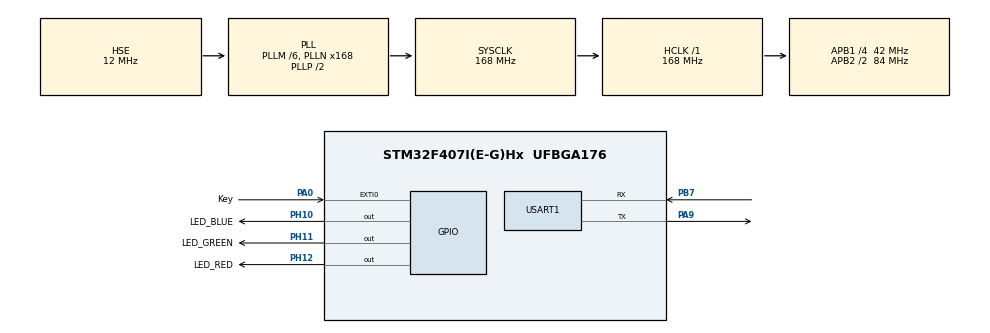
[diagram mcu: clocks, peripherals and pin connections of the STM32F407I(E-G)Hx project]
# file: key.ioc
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FREERTOS.BinarySemaphores01=KeyBinarySem,Dynamic,NULL,Depleted
FREERTOS.CountingSemaphores01=cryptoChip,3,Dynamic,NULL,3
FREERTOS.Queues01=usartQueue,32,AppMsg_t*,0,Dynamic,NULL,NULL
FREERTOS.Tasks01=defaultTask,24,128,StartDefaultTask,Default,NULL,Dynamic,NULL,NULL;LED_Flash_Task,8,128,Start_LED_Flash_Task,As weak,NULL,Dynamic,NULL,NULL;KeyTask,41,128,StartKeyTask,As weak,hkey,Dynamic,NULL,NULL;msgHandleTask,8,128,StartMsgHandleTask,As weak,NULL,Dynamic,NULL,NULL;myTask01,8,128,StartTask01,As weak,NULL,Dynamic,NULL,NULL;myTask02,8,128,StartTask02,As weak,NULL,Dynamic,NULL,NULL;myTask03,8,128,StartTask03,As weak,NULL,Dynamic,NULL,NULL
Mcu.Family=STM32F4
Mcu.Name=STM32F407I(E-G)Hx
Mcu.Package=UFBGA176
NVIC.EXTI0_IRQn=true\:5\:0\:false\:false\:true\:true\:true\:true\:true
NVIC.PriorityGroup=NVIC_PRIORITYGROUP_4
NVIC.TIM7_IRQn=true\:15\:0\:true\:false\:true\:false\:false\:true\:true
NVIC.TimeBase=TIM7_IRQn
NVIC.TimeBaseIP=TIM7
PA0-WKUP.GPIO_Label=Key
PA0-WKUP.GPIO_ModeDefaultEXTI=GPIO_MODE_IT_FALLING
PA0-WKUP.Signal=GPXTI0
PA13.Mode=Serial_Wire
PA13.Signal=SYS_JTMS-SWDIO
PA14.Mode=Serial_Wire
PA14.Signal=SYS_JTCK-SWCLK
PA9.Mode=Asynchronous
PA9.Signal=USART1_TX
PB7.Mode=Asynchronous
PB7.Signal=USART1_RX
PH0-OSC_IN.Mode=HSE-External-Oscillator
PH0-OSC_IN.Signal=RCC_OSC_IN
PH1-OSC_OUT.Mode=HSE-External-Oscillator
PH1-OSC_OUT.Signal=RCC_OSC_OUT
PH10.GPIO_Label=LED_BLUE
PH10.GPIO_PuPd=GPIO_PULLUP
PH10.Signal=GPIO_Output
PH11.GPIO_Label=LED_GREEN
PH11.GPIO_PuPd=GPIO_PULLUP
PH11.Signal=GPIO_Output
PH12.GPIO_Label=LED_RED
PH12.GPIO_PuPd=GPIO_PULLUP
PH12.Signal=GPIO_Output
ProjectManager.HeapSize=0x200
ProjectManager.StackSize=0x400
ProjectManager.TargetToolchain=CMake
RCC.48MHZClocksFreq_Value=84000000
RCC.AHBFreq_Value=168000000
RCC.APB1CLKDivider=RCC_HCLK_DIV4
RCC.APB1Freq_Value=42000000
RCC.APB1TimFreq_Value=84000000
RCC.APB2CLKDivider=RCC_HCLK_DIV2
RCC.APB2Freq_Value=84000000
RCC.APB2TimFreq_Value=168000000
RCC.CortexFreq_Value=168000000
RCC.HCLKFreq_Value=168000000
RCC.HSE_VALUE=12000000
RCC.HSI_VALUE=16000000
RCC.LSE_VALUE=32768
RCC.PLLM=6
RCC.PLLN=168
RCC.PLLSourceVirtual=RCC_PLLSOURCE_HSE
RCC.SYSCLKFreq_VALUE=168000000
RCC.SYSCLKSource=RCC_SYSCLKSOURCE_PLLCLK
RCC.VCOOutputFreq_Value=336000000
USART1.VirtualMode=VM_ASYNC
VP_FREERTOS_VS_CMSIS_V2.Mode=CMSIS_V2
VP_SYS_VS_tim7.Mode=TIM7
board=custom

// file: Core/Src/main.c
/* USER CODE BEGIN Header */
/**
 ******************************************************************************
 * @file           : main.c
 * @brief          : Main program body
 ******************************************************************************
 * @attention
 *
 * Copyright (c) 2026 STMicroelectronics.
 * All rights reserved.
 *
 * This software is licensed under terms that can be found in the LICENSE file
 * in the root directory of this software component.
 * If no LICENSE file comes with this software, it is provided AS-IS.
 *
 ******************************************************************************
 */
/* USER CODE END Header */
#include "main.h"
#include "cmsis_os.h"
#include "usart.h"
#include "gpio.h"

/* USER CODE BEGIN Includes */
#include "SEGGER_RTT.h"
#include "key.h"

/* USER CODE END Includes */

void SystemClock_Config(void);
void MX_FREERTOS_Init(void);

int main(void)
{

  /* MCU Configuration--------------------------------------------------------*/

  /* Reset of all peripherals, Initializes the Flash interface and the Systick. */
  HAL_Init();

  /* Configure the system clock */
  SystemClock_Config();

  /* Initialize all configured peripherals */
  MX_GPIO_Init();
  MX_USART1_UART_Init();

  /* Init scheduler */
  osKernelInitialize();  /* Call init function for freertos objects (in cmsis_os2.c) */
  MX_FREERTOS_Init();

  /* Start scheduler */
  osKernelStart();

  /* We should never get here as control is now taken by the scheduler */

  /* Infinite loop */
  while (1) {

  }
}

void SystemClock_Config(void)
{
  RCC_OscInitTypeDef RCC_OscInitStruct = {0};
  RCC_ClkInitTypeDef RCC_ClkInitStruct = {0};

  /** Configure the main internal regulator output voltage
  */
  __HAL_RCC_PWR_CLK_ENABLE();
  __HAL_PWR_VOLTAGESCALING_CONFIG(PWR_REGULATOR_VOLTAGE_SCALE1);

  /** Initializes the RCC Oscillators according to the specified parameters
  * in the RCC_OscInitTypeDef structure.
  */
  RCC_OscInitStruct.OscillatorType = RCC_OSCILLATORTYPE_HSE;
  RCC_OscInitStruct.HSEState = RCC_HSE_ON;
  RCC_OscInitStruct.PLL.PLLState = RCC_PLL_ON;
  RCC_OscInitStruct.PLL.PLLSource = RCC_PLLSOURCE_HSE;
  RCC_OscInitStruct.PLL.PLLM = 6;
  RCC_OscInitStruct.PLL.PLLN = 168;
  RCC_OscInitStruct.PLL.PLLP = RCC_PLLP_DIV2;
  RCC_OscInitStruct.PLL.PLLQ = 4;
  if (HAL_RCC_OscConfig(&RCC_OscInitStruct) != HAL_OK)
  {
    Error_Handler();
  }

  /** Initializes the CPU, AHB and APB buses clocks
  */
  RCC_ClkInitStruct.ClockType = RCC_CLOCKTYPE_HCLK|RCC_CLOCKTYPE_SYSCLK
                              |RCC_CLOCKTYPE_PCLK1|RCC_CLOCKTYPE_PCLK2;
  RCC_ClkInitStruct.SYSCLKSource = RCC_SYSCLKSOURCE_PLLCLK;
  RCC_ClkInitStruct.AHBCLKDivider = RCC_SYSCLK_DIV1;
  RCC_ClkInitStruct.APB1CLKDivider = RCC_HCLK_DIV4;
  RCC_ClkInitStruct.APB2CLKDivider = RCC_HCLK_DIV2;

  if (HAL_RCC_ClockConfig(&RCC_ClkInitStruct, FLASH_LATENCY_5) != HAL_OK)
  {
    Error_Handler();
  }
}

void HAL_TIM_PeriodElapsedCallback(TIM_HandleTypeDef *htim)
{
  if (htim->Instance == TIM7)
  {
    HAL_IncTick();
  }
}

void Error_Handler(void)
{
  __disable_irq();
  while (1) {
  }
}
#ifdef USE_FULL_ASSERT
/**
  * @brief  Reports the name of the source file and the source line number
  *         where the assert_param error has occurred.
  * @param  file: pointer to the source file name
  * @param  line: assert_param error line source number
  * @retval None
  */
void assert_failed(uint8_t *file, uint32_t line)
{
  /* USER CODE BEGIN 6 */
  /* User can add his own implementation to report the file name and line
     number, ex: printf("Wrong parameters value: file %s on line %d\r\n", file,
     line) */
  /* USER CODE END 6 */
}
#endif /* USE_FULL_ASSERT */

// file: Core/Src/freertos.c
/* USER CODE BEGIN Header */
/**
 ******************************************************************************
 * File Name          : freertos.c
 * Description        : Code for freertos applications
 ******************************************************************************
 * @attention
 *
 * Copyright (c) 2026 STMicroelectronics.
 * All rights reserved.
 *
 * This software is licensed under terms that can be found in the LICENSE file
 * in the root directory of this software component.
 * If no LICENSE file comes with this software, it is provided AS-IS.
 *
 ******************************************************************************
 */
/* USER CODE END Header */

#include "FreeRTOS.h"
#include "task.h"
#include "main.h"
#include "cmsis_os.h"

/* USER CODE BEGIN Includes */
#include "app_msg.h"
#include "key.h"
#include "key_task.h"
/* USER CODE END Includes */

/* Definitions for defaultTask */
osThreadId_t defaultTaskHandle;
const osThreadAttr_t defaultTask_attributes = {
  .name = "defaultTask",
  .stack_size = 128 * 4,
  .priority = (osPriority_t) osPriorityNormal,
};
/* Definitions for LED_Flash_Task */
osThreadId_t LED_Flash_TaskHandle;
const osThreadAttr_t LED_Flash_Task_attributes = {
  .name = "LED_Flash_Task",
  .stack_size = 128 * 4,
  .priority = (osPriority_t) osPriorityLow,
};
/* Definitions for KeyTask */
osThreadId_t KeyTaskHandle;
const osThreadAttr_t KeyTask_attributes = {
  .name = "KeyTask",
  .stack_size = 128 * 4,
  .priority = (osPriority_t) osPriorityHigh1,
};
/* Definitions for msgHandleTask */
osThreadId_t msgHandleTaskHandle;
const osThreadAttr_t msgHandleTask_attributes = {
  .name = "msgHandleTask",
  .stack_size = 128 * 4,
  .priority = (osPriority_t) osPriorityLow,
};
/* Definitions for myTask01 */
osThreadId_t myTask01Handle;
const osThreadAttr_t myTask01_attributes = {
  .name = "myTask01",
  .stack_size = 128 * 4,
  .priority = (osPriority_t) osPriorityLow,
};
/* Definitions for myTask02 */
osThreadId_t myTask02Handle;
const osThreadAttr_t myTask02_attributes = {
  .name = "myTask02",
  .stack_size = 128 * 4,
  .priority = (osPriority_t) osPriorityLow,
};
/* Definitions for myTask03 */
osThreadId_t myTask03Handle;
const osThreadAttr_t myTask03_attributes = {
  .name = "myTask03",
  .stack_size = 128 * 4,
  .priority = (osPriority_t) osPriorityLow,
};
/* Definitions for usartQueue */
osMessageQueueId_t usartQueueHandle;
const osMessageQueueAttr_t usartQueue_attributes = {
  .name = "usartQueue"
};
/* Definitions for KeyBinarySem */
osSemaphoreId_t KeyBinarySemHandle;
const osSemaphoreAttr_t KeyBinarySem_attributes = {
  .name = "KeyBinarySem"
};
/* Definitions for cryptoChip */
osSemaphoreId_t cryptoChipHandle;
const osSemaphoreAttr_t cryptoChip_attributes = {
  .name = "cryptoChip"
};

void StartDefaultTask(void *argument);
void Start_LED_Flash_Task(void *argument);
void StartKeyTask(void *argument);
void StartMsgHandleTask(void *argument);
void StartTask01(void *argument);
void StartTask02(void *argument);
void StartTask03(void *argument);

void MX_FREERTOS_Init(void); /* (MISRA C 2004 rule 8.1) */

void MX_FREERTOS_Init(void) {
  /* USER CODE BEGIN Init */
  AppMsg_Init();
  KEY_HandleTypeDef *hkey = Key_Create(Key_GPIO_Port, Key_Pin);
  if (hkey == NULL) {
    Error_Handler();
  }
  /* USER CODE END Init */

  /* Create the semaphores(s) */
  /* creation of KeyBinarySem */
  KeyBinarySemHandle = osSemaphoreNew(1, 0, &KeyBinarySem_attributes);

  /* creation of cryptoChip */
  cryptoChipHandle = osSemaphoreNew(3, 3, &cryptoChip_attributes);

  /* Create the queue(s) */
  /* creation of usartQueue */
  usartQueueHandle = osMessageQueueNew (16, sizeof(AppMsg_t*), &usartQueue_attributes);

  /* Create the thread(s) */
  /* creation of defaultTask */
  defaultTaskHandle = osThreadNew(StartDefaultTask, NULL, &defaultTask_attributes);

  /* creation of LED_Flash_Task */
  LED_Flash_TaskHandle = osThreadNew(Start_LED_Flash_Task, NULL, &LED_Flash_Task_attributes);

  /* creation of KeyTask */
  KeyTaskHandle = osThreadNew(StartKeyTask, (void*) hkey, &KeyTask_attributes);

  /* creation of msgHandleTask */
  msgHandleTaskHandle = osThreadNew(StartMsgHandleTask, NULL, &msgHandleTask_attributes);

  /* creation of myTask01 */
  myTask01Handle = osThreadNew(StartTask01, NULL, &myTask01_attributes);

  /* creation of myTask02 */
  myTask02Handle = osThreadNew(StartTask02, NULL, &myTask02_attributes);

  /* creation of myTask03 */
  myTask03Handle = osThreadNew(StartTask03, NULL, &myTask03_attributes);

}

void StartDefaultTask(void *argument)
{
  for (;;) {
    osDelay(1);
  }
}

__weak void Start_LED_Flash_Task(void *argument)
{
  for (;;) {
    osDelay(1);
  }
}

__weak void StartKeyTask(void *argument)
{
  for (;;) {
    osDelay(1);
  }
}

__weak void StartMsgHandleTask(void *argument)
{
  for (;;) {
    osDelay(1);
  }
}

__weak void StartTask01(void *argument)
{
  for (;;) {
    osDelay(1);
  }
}

__weak void StartTask02(void *argument)
{
  for (;;) {
    osDelay(1);
  }
}

__weak void StartTask03(void *argument)
{
  for (;;) {
    osDelay(1);
  }
}
